# pse84 register map
Vendor: Cypress Semiconductor; Series: PSE84; File version: 1.0
CPU: CM33 r0p1, little endian, MPU, FPU, VTOR, 3 interrupt priority bits
Registers are 32-bit, read-write, reset 0x0 unless marked. A register's access mark holds for its fields unless they carry their own. Offsets are from the block's base; [hi:lo] are bit positions; {n}, {i} and the like mark numbered series.

## ACTRLR (part 1 of 3) — Autonomnous Controller
Base 0x42ED0000
0x00 CTRL — control register
  [31] ENABLED — - 0: LPPASS IP disabled - 1: LPPASS IP enabled This field functions as the Global Enable for the LPPASS IP. This field must be set to gain read/write access to any other register in the LPPASS memory map. During initial IP release from reset (i.e. during POR), the LPPASS IP (along with its switched internal power domain) is disabled. After setting this bit, the LPPASS internal switched domain is powered up. The user must then wait for PWR_STATUS.SW_OK to assert. At this point, the user has read/write access to all LPPASS memory map registers. Clearing this field (i.e. disabling the LPPASS) can lead to status only clearing, or status and configuration clearing (see CFG.DISABLE_MODE).
0x04 CMD_RUN — run command register
  [0] RUN — Autonomous Controller Run Command Firmware should only write to this field when STATUS=STOPPED or PAUSED. When firmware sets this field, the Autonomous Controller starts running at the State pointed to by CMD_STATE. Hardware clears this field when the Autonomous Controller acknowledges the run command. If this field is set while STATUS=RUNNING, the Autonomous Controller will not respond to the command (beyond clearing the field). This register is reset whenever the following occurs: 1. The Autonomous Controller is disabled (clearing CTRL.ENABLED) 2. The LPPASS is configured for HS mode (STATUS.MODE=0) and the chip leaves an Active Mode.
0x08 CMD_STATE — state override register
  [5:0] STATE — Autonomous Controller Command State This field indicates where which AC State (0-63) the AC will execute instructions from when it receives a RUN or SINGLE_STEP command. Hardware updates this field whenever the AC transitions from RUNNING to STOPPED or PAUSED. When STOPPED or PAUSED, firmware can overrwrite this field to force the AC to execute from a specific STATE when triggered by a subsequent RUN or SINGLE_STEP command. This field must never be written to if STATUS=RUNNING. This register is reset whenever the following occurs: 1. The Autonomous Controller is disabled (clearing CTRL.ENABLED) 2. The LPPASS is configured for HS mode (STATUS.MODE=0) and the chip leaves an Active Mode.
{0x10+4i} FW_TR[{i}] (i=0..3) — firmware trigger
  [0] FW_TR — Firmware Trigger This field is used as a firmware trigger for the Autonomous Controller. The Autonomous Controller can be programmed to respond to the firmware trigger by programming a state with a condtion (COND) TR_LPPASS_IN*. Additionally, writing to this field will force the Autonomus Controller to wake from sleep. Hardware clears this bit when the Autonomous Controller acknowledges the trigger. This register is reset whenever the following occurs: 1. The Autonomous Controller is disabled (clearing CTRL.ENABLED) 2. The LPPASS is configured for HS mode (STATUS.MODE=0) and the chip leaves an Active Mode.
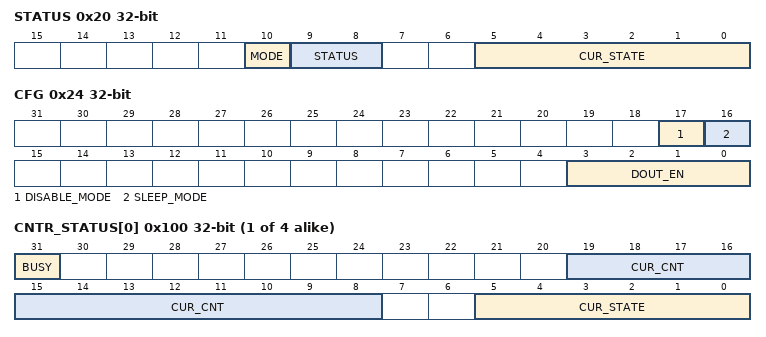
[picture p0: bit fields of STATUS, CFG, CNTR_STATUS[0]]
0x20 STATUS ro
  [10] MODE — This field indicates the mode of the Autonomous Controller. The Autonmous Controller always resets to HS mode. This field is reset whenever the following occurs: 1. The Autonomous Controller is disabled (clearing CTRL.ENABLED) 2. The LPPASS is configured for HS mode (STATUS.MODE=0) and the chip leaves an Active Mode.
    0=HS (Autonomous Controller is in High Speed (HS) mode In this mode, the LPPASS IP is functional only in chip Active modes. The LPPASS IP is clocked from a peripheral source derived from clk_hf.); 1=LP (Autonomous Controller is Low Power (LP) mode In this mode, the LPPASS IP is functional in both chip Active and Deepsleep modes. The LPPASS IP is clocked from the internal LPOSC.)
  [9:8] STATUS — Autonomous Controller status
    0=STOPPED (Autonomous Controller is stopped); 1=RUNNING (Autonomous Controller is running); 2=PAUSED (Autonomous Controller is paused); 3=RSVD (N/A)
  [5:0] CUR_STATE — This register indicates the current state of the Autonomous Controller (valid values are 0-63).
0x24 CFG — config register (only accessible if CTRL.EN=0)
  [17] DISABLE_MODE — Autonomous Controller Disable Mode -0 : Keep the LPPASS switched digital supply powered when the AC is disabled ( i.e. CTRL.ENABLED=0). - 1: Power Down the LPPASS digital supply when AC is disabled. This has the following consequences to the LPPASS: 1. Digital leakage is reduced (i.e. all logic on the LPPASS switched supply is powered off). 2. All LPPASS configuration is lost (all registers are reset and SRAMs lose data).
  [16] SLEEP_MODE — Autonomous Controller Sleep Mode -0 : Keep the LPPASS switched digital supply powered when the AC is sleeping (i.e. AC state programmed to action (ACT)=WAIT_FOR, and condition (COND)=wakeup source). - 1: Power Down the LPPASS digital supply when AC is asleep (i.e. AC ACT=WAIT_FOR, AC_COND= wakeup source). This has the following consequences to the LPPASS: 1. Digital leakage is reduced (i.e. all logic on the LPPASS switched supply is powered off). 2. CTBLs, SAR FIRs, and the DACs loose all configuration (i.e. they must be re-programmed to be functional again). 3. The wakeup time is increased by 3us ( to account for the switched power domain coming up).
  [3:0] DOUT_EN — DOUT output enable. Bits in this field must be set prior to writing to TIMER_TABLE_STRUCT.TT_CF0_DOUT. -0 : DOUT[X] output disabled - 1: DOUT[X] output enabled
0x30 DEBUG_PAUSE — pause debug register
  [0] PAUSE — Pause Command Setting this field requests the Autonomous Controller (AC) to pause. This field is used for debug purposes only. The AC waits for the present state to complete before pausing. If the present state cannot complete (i.e. the ACT and COND are programmed improperly), the AC will not pause. This command must not be used when executing an AC sleep state (ACT=WAIT_FOR and COND=WAKE_*). When the AC is paused, all AC registerd conditions are cleared. Hardware clears this bit when the Autonomous Controller is paused. This command is ignored if STATUS.STATUS is PAUSED or STOP.
0x34 DEBUG_SINGLE_STEP — single step debug register
  [0] SINGLE_STEP — Single Step Command Setting this field requests the Autonomous Controller (AC) to execute the next AC state (pointed to by CMD_STATE.STATE) and pause after completing that state. This field is used for debug purposes only. If the state (pointed to by CMD_STATE.STATE) cannot complete (i.e. the ACT and COND are programmed improperly), the AC will not pause at the end of the single step command. This command must not be used when executing an AC sleep state (ACT=WAIT_FOR and COND=*_WAKE). When the AC is paused, all AC registerd conditions are cleared. Hardware clears this bit when the Autonomous Controller pauses after executing the single step command. This command is ignored if STATUS.STATUS is RUNNING.
0x38 PWR_STATUS ro — power status register
  [0] SW_OK — This field indicates the status of the LPPASS switched power domain. This status should be polled whenever CTRL.EN toggles from a 0 to 1. 0: switched domain is powered off. 1: switched domain is powered on.
{0x100+4i} CNTR_STATUS[{i}] (i=0..3) ro — Loop/Interval counter status register
  [31] BUSY — This field indicates if the counter is busy (i.e. count value is non-zero).
  [19:8] CUR_CNT — This field indicates the count value for the given counter.
  [5:0] CUR_STATE — This field indicates the assigned Autonomous Controller (AC) State of a counter. Valid numbers are 0-63.
